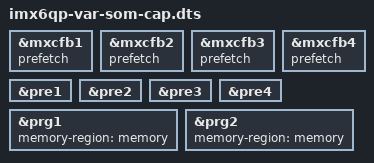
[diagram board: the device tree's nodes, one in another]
/*
 * Copyright (C) 2016 Variscite, Ltd. All Rights Reserved
 *
 * This program is free software; you can redistribute it and/or modify
 * it under the terms of the GNU General Public License version 2 as
 * published by the Free Software Foundation.
 */

#include "imx6q-var-som.dtsi"
#include "imx6qp.dtsi"
#include "imx6qdl-var-mx6cb-cdisplay.dtsi"

&mxcfb1 {
	prefetch;
};

&mxcfb2 {
	prefetch;
};

&mxcfb3 {
	prefetch;
};

&mxcfb4 {
	prefetch;
};

&pre1 {
	status = "okay";
};

&pre2 {
	status = "okay";
};

&pre3 {
	status = "okay";
};

&pre4 {
	status = "okay";
};

&prg1 {
	memory-region = <&memory>;
	status = "okay";
};

&prg2 {
	memory-region = <&memory>;
	status = "okay";
};
